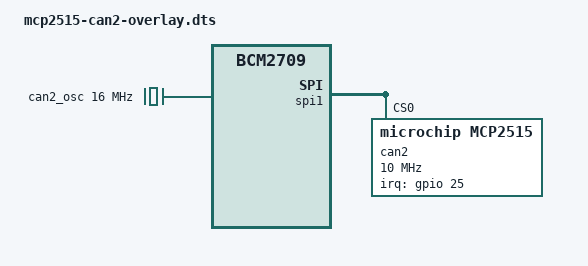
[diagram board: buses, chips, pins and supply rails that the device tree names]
/*
 * Device tree overlay for mcp251x/can2 on spi1.0
 */

/dts-v1/;
/plugin/;

/ {
    compatible = "brcm,bcm2835", "brcm,bcm2836", "brcm,bcm2708", "brcm,bcm2709";
    /* disable spi-dev for spi1.0 */
    fragment@0 {
        target = <&spi1>;
        __overlay__ {
            status = "okay";
            spidev@0{
                status = "disabled";
            };
        };
    };

    /* the interrupt pin of the can-controller */
    fragment@1 {
        target = <&gpio>;
        __overlay__ {
            can2_pins: can2_pins {
                brcm,pins = <25>;
                brcm,function = <0>; /* input */
            };
        };
    };

    /* the clock/oscillator of the can-controller */
    fragment@2 {
        target-path = "/clocks";
        __overlay__ {
            /* external oscillator of mcp2515 on SPI0.0 */
            can2_osc: can2_osc {
                compatible = "fixed-clock";
                #clock-cells = <0>;
                clock-frequency  = <16000000>;
            };
        };
    };

    /* the spi config of the can-controller itself binding everything together */
    fragment@3 {
        target = <&spi1>;
        __overlay__ {
            /* needed to avoid dtc warning */
            #address-cells = <1>;
            #size-cells = <0>;
            can2: mcp2515@0 {
                reg = <0>;
                compatible = "microchip,mcp2515";
                pinctrl-names = "default";
                pinctrl-0 = <&can2_pins>;
                spi-max-frequency = <10000000>;
                interrupt-parent = <&gpio>;
                interrupts = <25 0x8>;
                clocks = <&can2_osc>;
            };
        };
    };
    __overrides__ {
        oscillator = <&can2_osc>,"clock-frequency:0";
        spimaxfrequency = <&can2>,"spi-max-frequency:0";
        interrupt = <&can2_pins>,"brcm,pins:0",<&can2>,"interrupts:0";
    };
};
